# STM32G491xx register map
File version: 1.4
CPU: CM4 r0p1, little endian, MPU, FPU, 4 interrupt priority bits
Registers are 32-bit, read-write, reset 0x0 unless marked. A register's access mark holds for its fields unless they carry their own. Offsets are from the block's base; [hi:lo] are bit positions; lines under a group give offsets from that group; {n}, {i} and the like mark numbered series; 'fields as' and 'values as' point back to an identical list.

## SYSCFG — System configuration controller
Base 0x40010000
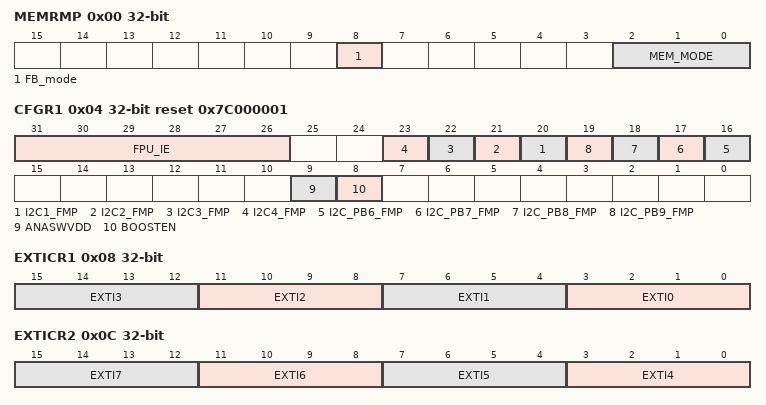
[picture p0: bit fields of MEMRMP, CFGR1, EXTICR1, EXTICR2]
0x00 MEMRMP — Remap Memory register
  [8] FB_mode — User Flash Bank mode
  [2:0] MEM_MODE — Memory mapping selection
0x04 CFGR1 reset 0x7C000001 — peripheral mode configuration register
  [31:26] FPU_IE — FPU Interrupts Enable
  [n+19] I2C{n}_FMP (n=1..4) — I2C1 FM+ drive capability enable
  [n+10] I2C_PB{n}_FMP (n=6..9) — FM+ drive capability on PB6
  [9] ANASWVDD — GPIO analog switch control voltage selection
  [8] BOOSTEN
0x08 EXTICR1 — external interrupt configuration register 1
  [4n+3:4n] EXTI{n} (n=0..3) — EXTI x configuration (x = 0 to 3)
0x0C EXTICR2 — external interrupt configuration register 2
  [4n-13:4n-16] EXTI{n} (n=4..7) — EXTI x configuration (x = 4 to 7)
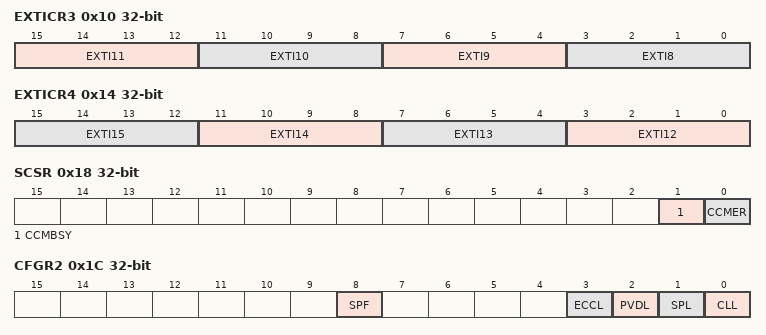
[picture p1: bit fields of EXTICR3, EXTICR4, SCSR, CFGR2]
0x10 EXTICR3 — external interrupt configuration register 3
  [15:12] EXTI11 — EXTI x configuration (x = 8 to 11)
  [11:8] EXTI10
  [7:4] EXTI9 — EXTI x configuration (x = 8 to 11)
  [3:0] EXTI8 — EXTI x configuration (x = 8 to 11)
0x14 EXTICR4 — external interrupt configuration register 4
  [4n-45:4n-48] EXTI{n} (n=12..15) — EXTI x configuration (x = 12 to 15)
0x18 SCSR access per field — CCM SRAM control and status register
  [1] CCMBSY ro — CCM SRAM busy by erase operation
  [0] CCMER rw — CCM SRAM Erase
0x1C CFGR2 — configuration register 2
  [8] SPF — SRAM Parity Flag
  [3] ECCL — ECC Lock
  [2] PVDL — PVD Lock
  [1] SPL — SRAM Parity Lock
  [0] CLL — Core Lockup Lock
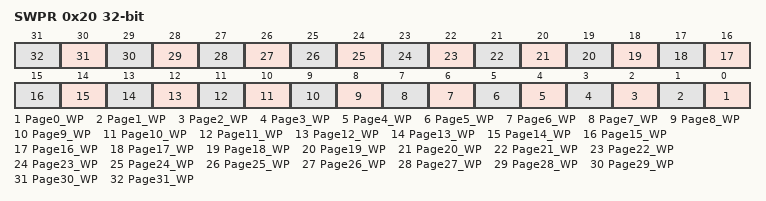
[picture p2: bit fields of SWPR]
0x20 SWPR — SRAM Write protection register 1
  [n] Page{n}_WP (n=0..31) — Write protection
0x24 SKR wo — SRAM2 Key Register
  [7:0] KEY — SRAM2 Key for software erase

## VREFBUF — Voltage reference buffer
Base 0x40010030
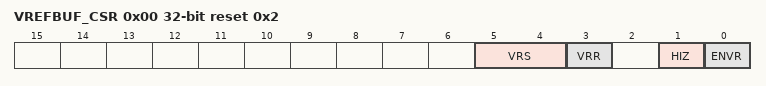
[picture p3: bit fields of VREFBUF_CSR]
0x00 VREFBUF_CSR access per field reset 0x2 — VREF_BUF Control and Status Register
  [5:4] VRS rw — Voltage reference scale
  [3] VRR ro — Voltage reference buffer ready
  [1] HIZ rw — High impedence mode for the VREF_BUF
  [0] ENVR rw — Enable Voltage Reference
0x04 VREFBUF_CCR — VREF_BUF Calibration Control Register
  [5:0] TRIM — Trimming code

## COMP — Comparator control and status register
Base 0x40010200
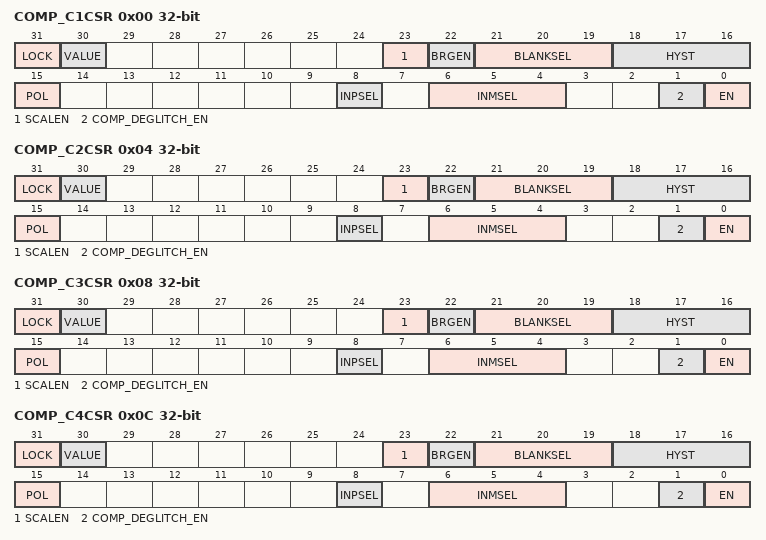
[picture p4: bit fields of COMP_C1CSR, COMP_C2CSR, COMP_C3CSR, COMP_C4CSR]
0x00 COMP_C1CSR access per field — Comparator control/status register
  [31] LOCK rw, [30] VALUE ro, [23] SCALEN rw, [22] BRGEN rw, [21:19] BLANKSEL rw, [18:16] HYST rw, [15] POL rw, [8] INPSEL rw, [6:4] INMSEL rw, [1] COMP_DEGLITCH_EN rw, [0] EN rw
0x04 COMP_C2CSR access per field — Comparator control/status register
  fields as COMP_C1CSR
0x08 COMP_C3CSR access per field — Comparator control/status register
  fields as COMP_C1CSR
0x0C COMP_C4CSR access per field — Comparator control/status register
  fields as COMP_C1CSR

## OPAMP — Operational amplifiers
Base 0x40010300
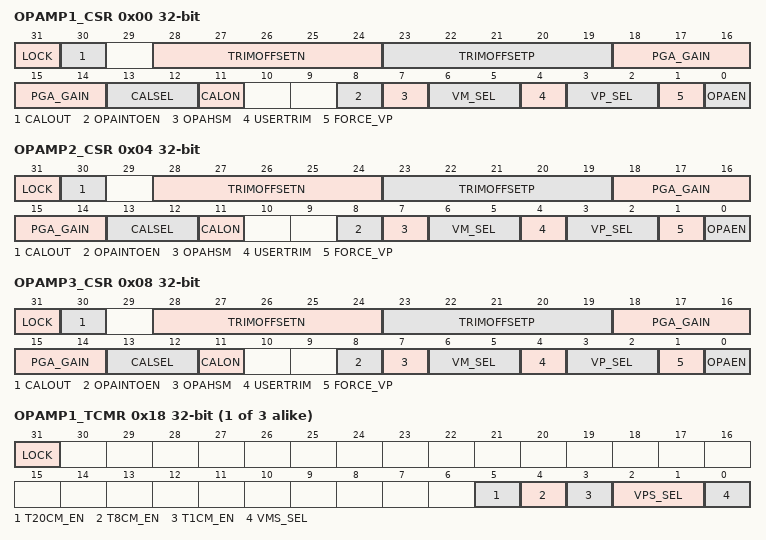
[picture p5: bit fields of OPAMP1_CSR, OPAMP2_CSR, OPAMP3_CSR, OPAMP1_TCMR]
0x00 OPAMP1_CSR — OPAMP1 control/status register
  [31] LOCK
  [30] CALOUT
  [28:24] TRIMOFFSETN
  [23:19] TRIMOFFSETP
  [18:14] PGA_GAIN
  [13:12] CALSEL
  [11] CALON
  [8] OPAINTOEN
  [7] OPAHSM
  [6:5] VM_SEL
  [4] USERTRIM
  [3:2] VP_SEL
  [1] FORCE_VP
  [0] OPAEN — Operational amplifier Enable
0x04 OPAMP2_CSR — OPAMP2 control/status register
  fields as OPAMP1_CSR
0x08 OPAMP3_CSR — OPAMP3 control/status register
  fields as OPAMP1_CSR
{0x14+4i} OPAMP{i}_TCMR (i=1..3) — OPAMP{i} control/status register
  [31] LOCK, [5] T20CM_EN, [4] T8CM_EN, [3] T1CM_EN, [2:1] VPS_SEL, [0] VMS_SEL

## ADC1 — Analog-to-Digital Converter
Base 0x50000000
Same registers: ADC2 0x50000100
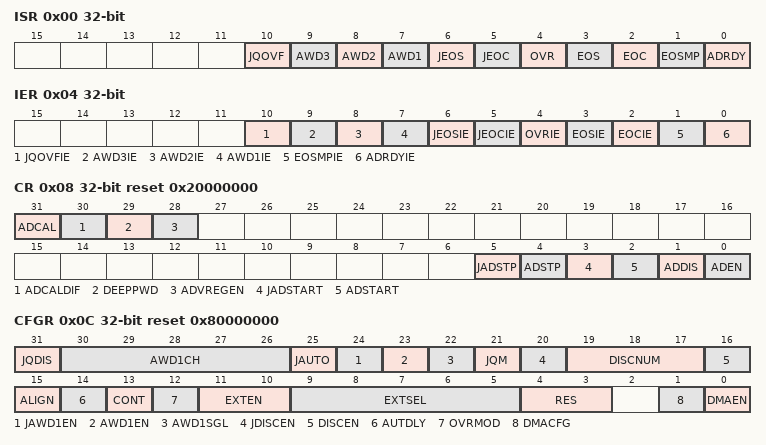
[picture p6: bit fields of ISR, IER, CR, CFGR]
0x00 ISR — interrupt and status register
  [10] JQOVF, [9] AWD3, [8] AWD2, [7] AWD1, [6] JEOS, [5] JEOC, [4] OVR, [3] EOS, [2] EOC, [1] EOSMP, [0] ADRDY
0x04 IER — interrupt enable register
  [10] JQOVFIE, [9] AWD3IE, [8] AWD2IE, [7] AWD1IE, [6] JEOSIE, [5] JEOCIE, [4] OVRIE, [3] EOSIE, [2] EOCIE, [1] EOSMPIE, [0] ADRDYIE
0x08 CR reset 0x20000000 — control register
  [31] ADCAL, [30] ADCALDIF, [29] DEEPPWD, [28] ADVREGEN, [5] JADSTP, [4] ADSTP, [3] JADSTART, [2] ADSTART, [1] ADDIS, [0] ADEN
0x0C CFGR reset 0x80000000 — configuration register
  [31] JQDIS — Injected Queue disable
  [30:26] AWD1CH — Analog watchdog 1 channel selection
  [25] JAUTO
  [24] JAWD1EN
  [23] AWD1EN
  [22] AWD1SGL
  [21] JQM
  [20] JDISCEN
  [19:17] DISCNUM
  [16] DISCEN
  [15] ALIGN
  [14] AUTDLY
  [13] CONT
  [12] OVRMOD
  [11:10] EXTEN
  [9:5] EXTSEL — External trigger selection for regular group
  [4:3] RES
  [1] DMACFG
  [0] DMAEN
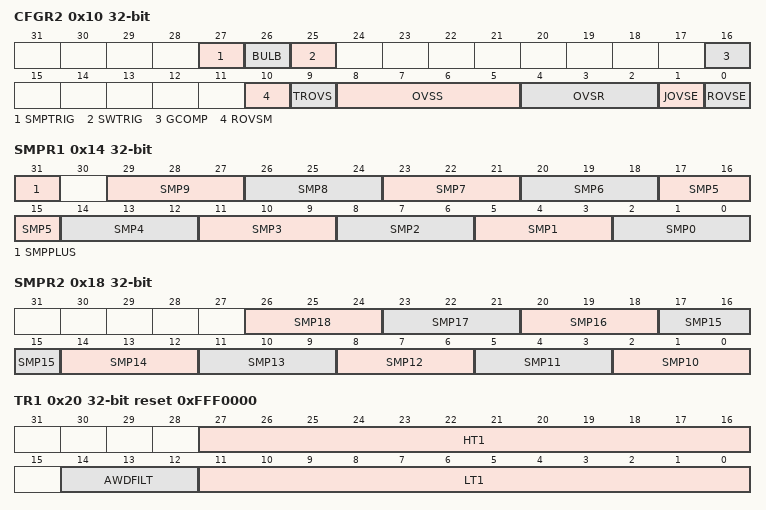
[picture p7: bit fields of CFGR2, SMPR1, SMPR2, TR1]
0x10 CFGR2 — configuration register
  [27] SMPTRIG
  [26] BULB
  [25] SWTRIG
  [16] GCOMP
  [10] ROVSM — EXTEN
  [9] TROVS — Triggered Regular Oversampling
  [8:5] OVSS — ALIGN
  [4:2] OVSR — RES
  [1] JOVSE — DMACFG
  [0] ROVSE — DMAEN
0x14 SMPR1 — sample time register 1
  [31] SMPPLUS — Addition of one clock cycle to the sampling time
  [3n+2:3n] SMP{n} (n=0..9)
0x18 SMPR2 — sample time register 2
  [3n-28:3n-30] SMP{n} (n=10..18)
0x20 TR1 reset 0xFFF0000 — watchdog threshold register 1
  [27:16] HT1, [14:12] AWDFILT, [11:0] LT1
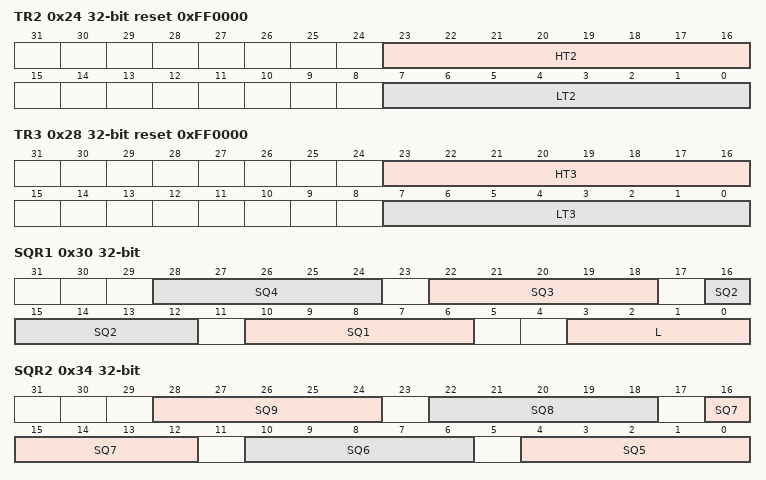
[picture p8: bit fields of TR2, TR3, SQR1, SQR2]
0x24 TR2 reset 0xFF0000 — watchdog threshold register
  [23:16] HT2, [7:0] LT2
0x28 TR3 reset 0xFF0000 — watchdog threshold register 3
  [23:16] HT3, [7:0] LT3
0x30 SQR1 — regular sequence register 1
  [6n+4:6n] SQ{n} (n=1..4)
  [3:0] L — Regular channel sequence length
0x34 SQR2 — regular sequence register 2
  [6n-26:6n-30] SQ{n} (n=5..9)
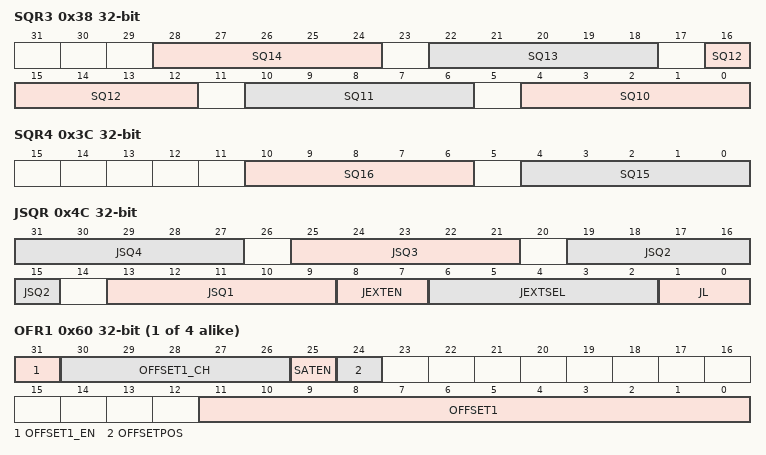
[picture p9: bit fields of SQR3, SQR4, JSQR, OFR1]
0x38 SQR3 — regular sequence register 3
  [6n-56:6n-60] SQ{n} (n=10..14)
0x3C SQR4 — regular sequence register 4
  [10:6] SQ16, [4:0] SQ15
0x40 DR ro — regular Data Register
  [15:0] RDATA — Regular Data converted
0x4C JSQR — injected sequence register
  [6n+7:6n+3] JSQ{n} (n=1..4), [8:7] JEXTEN, [6:2] JEXTSEL, [1:0] JL
{0x5C+4i} OFR{i} (i=1..4) — offset register {i}
  [31] OFFSET1_EN, [30:26] OFFSET1_CH, [25] SATEN, [24] OFFSETPOS, [11:0] OFFSET1
{0x7C+4i} JDR{i} ro (i=1..4) — injected data register {i}
  [15:0] JDATA{i}
0xA0 AWD2CR — Analog Watchdog 2 Configuration Register
  [18:0] AWD2CH
0xA4 AWD3CR — Analog Watchdog 3 Configuration Register
  [18:0] AWD3CH
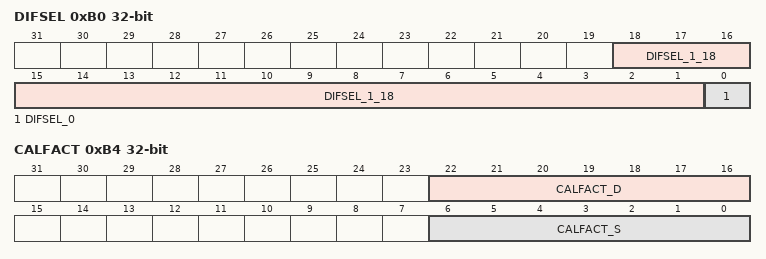
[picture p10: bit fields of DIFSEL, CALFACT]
0xB0 DIFSEL access per field — Differential Mode Selection Register 2
  [18:1] DIFSEL_1_18 rw — Differential mode for channels 15 to 1
  [0] DIFSEL_0 ro — Differential mode for channels 0
0xB4 CALFACT — Calibration Factors
  [22:16] CALFACT_D, [6:0] CALFACT_S
0xC0 GCOMP — Gain compensation Register
  [13:0] GCOMPCOEFF

## ADC3 — Analog-to-Digital Converter
Base 0x50000400
Registers as ADC1; these are added or differ:
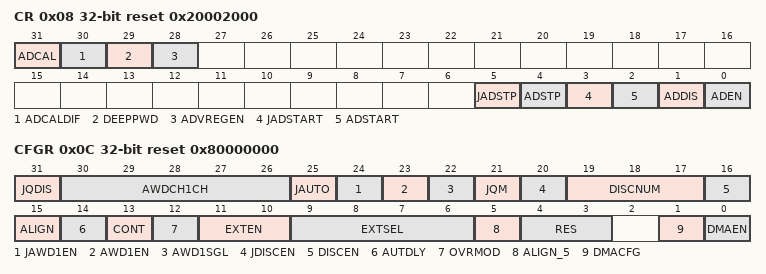
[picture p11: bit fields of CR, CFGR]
0x08 CR reset 0x20002000 — control register
  [31] ADCAL, [30] ADCALDIF, [29] DEEPPWD, [28] ADVREGEN, [5] JADSTP, [4] ADSTP, [3] JADSTART, [2] ADSTART, [1] ADDIS, [0] ADEN
0x0C CFGR reset 0x80000000 — configuration register
  [31] JQDIS — Injected Queue disable
  [30:26] AWDCH1CH
  [25] JAUTO
  [24] JAWD1EN
  [23] AWD1EN
  [22] AWD1SGL
  [21] JQM
  [20] JDISCEN
  [19:17] DISCNUM
  [16] DISCEN
  [15] ALIGN
  [14] AUTDLY
  [13] CONT
  [12] OVRMOD
  [11:10] EXTEN
  [9:6] EXTSEL
  [5] ALIGN_5
  [4:3] RES
  [1] DMACFG
  [0] DMAEN
